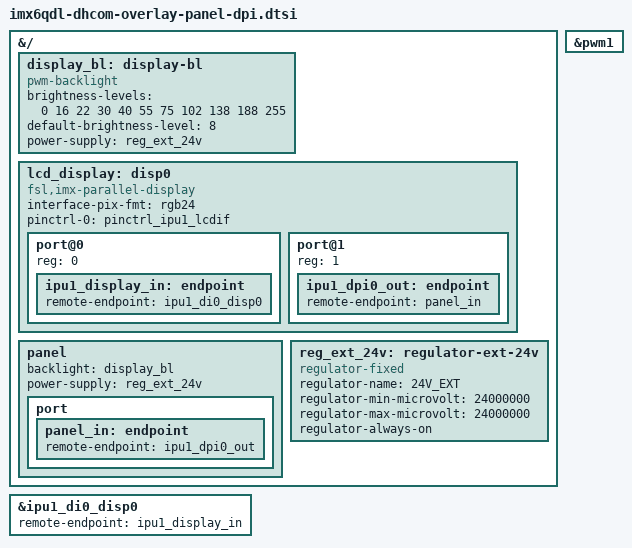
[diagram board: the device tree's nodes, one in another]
// SPDX-License-Identifier: (GPL-2.0+ OR BSD-3-Clause)
/*
 * Copyright (C) 2021 Marek Vasut <marex@denx.de>
 * Copyright (C) 2022 DH electronics GmbH
 */
#include <dt-bindings/gpio/gpio.h>
#include <dt-bindings/input/input.h>
#include <dt-bindings/interrupt-controller/arm-gic.h>
#include <dt-bindings/pwm/pwm.h>

&{/} {
	#address-cells = <1>;
	#size-cells = <1>;

	display_bl: display-bl {
		compatible = "pwm-backlight";
		brightness-levels = <0 16 22 30 40 55 75 102 138 188 255>;
		default-brightness-level = <8>;
		power-supply = <&reg_ext_24v>;
	};

	lcd_display: disp0 {
		compatible = "fsl,imx-parallel-display";
		#address-cells = <1>;
		#size-cells = <0>;
		interface-pix-fmt = "rgb24";
		pinctrl-0 = <&pinctrl_ipu1_lcdif>;
		pinctrl-names = "default";

		port@0 {
			reg = <0>;

			ipu1_display_in: endpoint {
				remote-endpoint = <&ipu1_di0_disp0>;
			};
		};

		port@1 {
			reg = <1>;

			ipu1_dpi0_out: endpoint {
				remote-endpoint = <&panel_in>;
			};
		};
	};

	panel: panel {
		backlight = <&display_bl>;
		power-supply = <&reg_ext_24v>;

		port {
			panel_in: endpoint {
				remote-endpoint = <&ipu1_dpi0_out>;
			};
		};
	};

	reg_ext_24v: regulator-ext-24v {
		compatible = "regulator-fixed";
		regulator-name = "24V_EXT";
		regulator-min-microvolt = <24000000>;
		regulator-max-microvolt = <24000000>;
		regulator-always-on;
	};
};

&ipu1_di0_disp0 {
	remote-endpoint = <&ipu1_display_in>;
};

&pwm1 {
	status = "okay";
};
